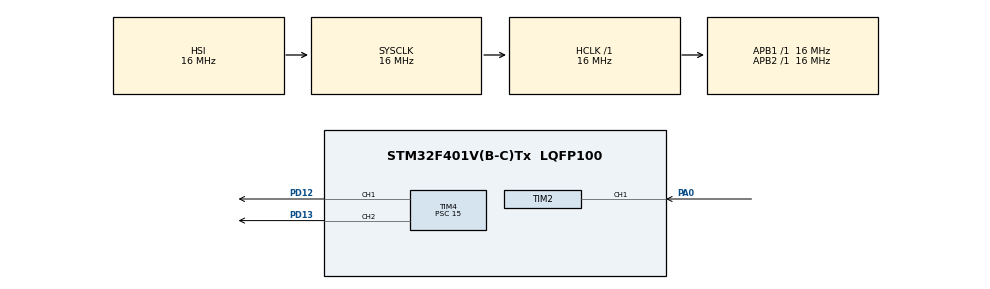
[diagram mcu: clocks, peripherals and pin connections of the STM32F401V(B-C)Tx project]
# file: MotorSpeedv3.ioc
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Mcu.Family=STM32F4
Mcu.Name=STM32F401V(B-C)Tx
Mcu.Package=LQFP100
NVIC.PriorityGroup=NVIC_PRIORITYGROUP_4
NVIC.TIM2_IRQn=true\:0\:0\:false\:false\:true\:true
NVIC.TIM4_IRQn=true\:0\:0\:false\:false\:true\:true
PA0-WKUP.Signal=S_TIM2_CH1_ETR
PD12.Signal=S_TIM4_CH1
PD13.Signal=S_TIM4_CH2
ProjectManager.HeapSize=0x200
ProjectManager.StackSize=0x400
ProjectManager.TargetToolchain=MDK-ARM V5
RCC.AHBFreq_Value=16000000
RCC.APB1Freq_Value=16000000
RCC.APB2Freq_Value=16000000
RCC.CortexFreq_Value=16000000
RCC.HSE_VALUE=25000000
RCC.HSI_VALUE=16000000
RCC.LSE_VALUE=32768
RCC.SYSCLKFreq_VALUE=16000000
RCC.VCOOutputFreq_Value=192000000
SH.S_TIM2_CH1_ETR.0=TIM2_CH1,Input_Capture1_from_TI1
SH.S_TIM4_CH1.0=TIM4_CH1,PWM Generation1 CH1
SH.S_TIM4_CH2.0=TIM4_CH2,PWM Generation2 CH2
TIM2.Channel-Input_Capture1_from_TI1=TIM_CHANNEL_1
TIM2.ICFilter_CH1=15
TIM2.Period=4294967295
TIM2.Prescaler=1599
TIM4.Channel-PWM\ Generation1\ CH1=TIM_CHANNEL_1
TIM4.Channel-PWM\ Generation2\ CH2=TIM_CHANNEL_2
TIM4.Period=99
TIM4.Prescaler=15
VP_TIM2_VS_ClockSourceINT.Mode=Internal
VP_TIM4_VS_ClockSourceINT.Mode=Internal
board=MotorSpeedv3

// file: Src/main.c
/**
  ******************************************************************************
  * File Name          : main.c
  * Description        : Main program body
  ******************************************************************************
  ** This notice applies to any and all portions of this file
  * that are not between comment pairs USER CODE BEGIN and
  * USER CODE END. Other portions of this file, whether
  * inserted by the user or by software development tools
  * are owned by their respective copyright owners.
  *
  * COPYRIGHT(c) 2017 STMicroelectronics
  *
  * Redistribution and use in source and binary forms, with or without modification,
  * are permitted provided that the following conditions are met:
  *   1. Redistributions of source code must retain the above copyright notice,
  *      this list of conditions and the following disclaimer.
  *   2. Redistributions in binary form must reproduce the above copyright notice,
  *      this list of conditions and the following disclaimer in the documentation
  *      and/or other materials provided with the distribution.
  *   3. Neither the name of STMicroelectronics nor the names of its contributors
  *      may be used to endorse or promote products derived from this software
  *      without specific prior written permission.
  *
  * THIS SOFTWARE IS PROVIDED BY THE COPYRIGHT HOLDERS AND CONTRIBUTORS "AS IS"
  * AND ANY EXPRESS OR IMPLIED WARRANTIES, INCLUDING, BUT NOT LIMITED TO, THE
  * IMPLIED WARRANTIES OF MERCHANTABILITY AND FITNESS FOR A PARTICULAR PURPOSE ARE
  * DISCLAIMED. IN NO EVENT SHALL THE COPYRIGHT HOLDER OR CONTRIBUTORS BE LIABLE
  * FOR ANY DIRECT, INDIRECT, INCIDENTAL, SPECIAL, EXEMPLARY, OR CONSEQUENTIAL
  * DAMAGES (INCLUDING, BUT NOT LIMITED TO, PROCUREMENT OF SUBSTITUTE GOODS OR
  * SERVICES; LOSS OF USE, DATA, OR PROFITS; OR BUSINESS INTERRUPTION) HOWEVER
  * CAUSED AND ON ANY THEORY OF LIABILITY, WHETHER IN CONTRACT, STRICT LIABILITY,
  * OR TORT (INCLUDING NEGLIGENCE OR OTHERWISE) ARISING IN ANY WAY OUT OF THE USE
  * OF THIS SOFTWARE, EVEN IF ADVISED OF THE POSSIBILITY OF SUCH DAMAGE.
  *
  ******************************************************************************
  */
#include "main.h"
#include "stm32f4xx_hal.h"

/* USER CODE BEGIN Includes */
#define SIZE 10
//#define KP 0.5
//#define KI 0.1
//#define KD 0.01
#define KP 1
#define KI 0.1
#define KD 0.1
/* USER CODE END Includes */

TIM_HandleTypeDef htim2;
TIM_HandleTypeDef htim4;

/* USER CODE BEGIN PV */
/* Private variables ---------------------------------------------------------*/
	int i = 0, j = 0;
	int pwm = 99, max_pwm = 99;
	int open_loop_speed = 270;
	int reference = 0;
	int slots = 20;
	long count = 0;
	int ticks = 0;
	long cur_val = 0, prev_val = 0;
	double speed_rpm = 0, avg_speed = 0, sum_speed = 0;
	double prev_speeds [SIZE];
	double PID = 0, Kp = 0, Ki = 0, Kd = 0;
	double delT = 0;
	double error = 0, prev_err = 0;
	double int_err = 0, der_err = 0;
/* USER CODE END PV */

void SystemClock_Config(void);
static void MX_GPIO_Init(void);
static void MX_TIM4_Init(void);
static void MX_TIM2_Init(void);

void HAL_TIM_MspPostInit(TIM_HandleTypeDef *htim);

/* USER CODE BEGIN PFP */
/* Private function prototypes -----------------------------------------------*/

/* USER CODE END PFP */

/* USER CODE BEGIN 0 */
void HAL_TIM_IC_CaptureCallback(TIM_HandleTypeDef *htim)
{
	if(htim->Instance==TIM2)
	{
		reference = 120;

		if(j >= SIZE) j = 0;
		prev_speeds[j++]= speed_rpm;

		prev_val = cur_val;
		cur_val = HAL_TIM_ReadCapturedValue(&htim2, TIM_CHANNEL_1);
    ticks = cur_val - prev_val;
		speed_rpm = (60 * 10000) / (ticks * slots);

		avg_speed = (speed_rpm + prev_speeds[0] + prev_speeds[1] + prev_speeds[2] + prev_speeds[3] + prev_speeds[4] + prev_speeds[5] + prev_speeds[6] + prev_speeds[7] + prev_speeds[8] + prev_speeds[9]) / 11;
		if (i++ == 0) error = 120;
		else error = reference - speed_rpm;
		delT = (double) ticks / 10000;

		int_err += (error * delT);
		der_err = (error - prev_err) / delT;
		PID = Kp*error + Ki*int_err + Kd*der_err;

//		pwm += ((max_pwm * PID) / reference);
		pwm += ((max_pwm * PID) / open_loop_speed);
		if(pwm > max_pwm) pwm = max_pwm;
		if(pwm < 0) pwm = 0;

		__HAL_TIM_SetCompare(&htim4, TIM_CHANNEL_1, pwm);
		prev_err = error;
	}
}

void HAL_TIM_PWM_PulseFinishedCallback(TIM_HandleTypeDef *htim)
{
	if(htim->Instance==TIM4)
	{
		count = __HAL_TIM_GetCounter(&htim2);
		if(count - cur_val >= 1000)
		{
			speed_rpm = 0;
			avg_speed = 0;
		}
	}
}
/* USER CODE END 0 */

int main(void)
{

  /* MCU Configuration----------------------------------------------------------*/

  /* Reset of all peripherals, Initializes the Flash interface and the Systick. */
  HAL_Init();

  /* Configure the system clock */
  SystemClock_Config();

  /* Initialize all configured peripherals */
  MX_GPIO_Init();
  MX_TIM4_Init();
  MX_TIM2_Init();

  /* USER CODE BEGIN 2 */
	HAL_TIM_PWM_Start_IT(&htim4, TIM_CHANNEL_1);
	HAL_TIM_PWM_Start(&htim4, TIM_CHANNEL_2);
	HAL_TIM_IC_Start_IT(&htim2, TIM_CHANNEL_1);

	Kp = KP;
	Ki = KI;
	Kd = KD;

	__HAL_TIM_SetCompare(&htim4, TIM_CHANNEL_1, pwm);
	__HAL_TIM_SetCompare(&htim4, TIM_CHANNEL_2, 0);
  /* USER CODE END 2 */

  /* Infinite loop */
  while (1)
  {

  }

}

/** System Clock Configuration
*/
void SystemClock_Config(void)
{

  RCC_OscInitTypeDef RCC_OscInitStruct;
  RCC_ClkInitTypeDef RCC_ClkInitStruct;

    /**Configure the main internal regulator output voltage
    */
  __HAL_RCC_PWR_CLK_ENABLE();

  __HAL_PWR_VOLTAGESCALING_CONFIG(PWR_REGULATOR_VOLTAGE_SCALE2);

    /**Initializes the CPU, AHB and APB busses clocks
    */
  RCC_OscInitStruct.OscillatorType = RCC_OSCILLATORTYPE_HSI;
  RCC_OscInitStruct.HSIState = RCC_HSI_ON;
  RCC_OscInitStruct.HSICalibrationValue = 16;
  RCC_OscInitStruct.PLL.PLLState = RCC_PLL_NONE;
  if (HAL_RCC_OscConfig(&RCC_OscInitStruct) != HAL_OK)
  {
    _Error_Handler(__FILE__, __LINE__);
  }

    /**Initializes the CPU, AHB and APB busses clocks
    */
  RCC_ClkInitStruct.ClockType = RCC_CLOCKTYPE_HCLK|RCC_CLOCKTYPE_SYSCLK
                              |RCC_CLOCKTYPE_PCLK1|RCC_CLOCKTYPE_PCLK2;
  RCC_ClkInitStruct.SYSCLKSource = RCC_SYSCLKSOURCE_HSI;
  RCC_ClkInitStruct.AHBCLKDivider = RCC_SYSCLK_DIV1;
  RCC_ClkInitStruct.APB1CLKDivider = RCC_HCLK_DIV1;
  RCC_ClkInitStruct.APB2CLKDivider = RCC_HCLK_DIV1;

  if (HAL_RCC_ClockConfig(&RCC_ClkInitStruct, FLASH_LATENCY_0) != HAL_OK)
  {
    _Error_Handler(__FILE__, __LINE__);
  }

    /**Configure the Systick interrupt time
    */
  HAL_SYSTICK_Config(HAL_RCC_GetHCLKFreq()/1000);

    /**Configure the Systick
    */
  HAL_SYSTICK_CLKSourceConfig(SYSTICK_CLKSOURCE_HCLK);

  /* SysTick_IRQn interrupt configuration */
  HAL_NVIC_SetPriority(SysTick_IRQn, 0, 0);
}

/* TIM2 init function */
static void MX_TIM2_Init(void)
{

  TIM_ClockConfigTypeDef sClockSourceConfig;
  TIM_MasterConfigTypeDef sMasterConfig;
  TIM_IC_InitTypeDef sConfigIC;

  htim2.Instance = TIM2;
  htim2.Init.Prescaler = 1599;
  htim2.Init.CounterMode = TIM_COUNTERMODE_UP;
  htim2.Init.Period = 4294967295;
  htim2.Init.ClockDivision = TIM_CLOCKDIVISION_DIV1;
  if (HAL_TIM_Base_Init(&htim2) != HAL_OK)
  {
    _Error_Handler(__FILE__, __LINE__);
  }

  sClockSourceConfig.ClockSource = TIM_CLOCKSOURCE_INTERNAL;
  if (HAL_TIM_ConfigClockSource(&htim2, &sClockSourceConfig) != HAL_OK)
  {
    _Error_Handler(__FILE__, __LINE__);
  }

  if (HAL_TIM_IC_Init(&htim2) != HAL_OK)
  {
    _Error_Handler(__FILE__, __LINE__);
  }

  sMasterConfig.MasterOutputTrigger = TIM_TRGO_RESET;
  sMasterConfig.MasterSlaveMode = TIM_MASTERSLAVEMODE_DISABLE;
  if (HAL_TIMEx_MasterConfigSynchronization(&htim2, &sMasterConfig) != HAL_OK)
  {
    _Error_Handler(__FILE__, __LINE__);
  }

  sConfigIC.ICPolarity = TIM_INPUTCHANNELPOLARITY_RISING;
  sConfigIC.ICSelection = TIM_ICSELECTION_DIRECTTI;
  sConfigIC.ICPrescaler = TIM_ICPSC_DIV1;
  sConfigIC.ICFilter = 15;
  if (HAL_TIM_IC_ConfigChannel(&htim2, &sConfigIC, TIM_CHANNEL_1) != HAL_OK)
  {
    _Error_Handler(__FILE__, __LINE__);
  }

}

/* TIM4 init function */
static void MX_TIM4_Init(void)
{

  TIM_ClockConfigTypeDef sClockSourceConfig;
  TIM_MasterConfigTypeDef sMasterConfig;
  TIM_OC_InitTypeDef sConfigOC;

  htim4.Instance = TIM4;
  htim4.Init.Prescaler = 15;
  htim4.Init.CounterMode = TIM_COUNTERMODE_UP;
  htim4.Init.Period = 99;
  htim4.Init.ClockDivision = TIM_CLOCKDIVISION_DIV1;
  if (HAL_TIM_Base_Init(&htim4) != HAL_OK)
  {
    _Error_Handler(__FILE__, __LINE__);
  }

  sClockSourceConfig.ClockSource = TIM_CLOCKSOURCE_INTERNAL;
  if (HAL_TIM_ConfigClockSource(&htim4, &sClockSourceConfig) != HAL_OK)
  {
    _Error_Handler(__FILE__, __LINE__);
  }

  if (HAL_TIM_PWM_Init(&htim4) != HAL_OK)
  {
    _Error_Handler(__FILE__, __LINE__);
  }

  sMasterConfig.MasterOutputTrigger = TIM_TRGO_RESET;
  sMasterConfig.MasterSlaveMode = TIM_MASTERSLAVEMODE_DISABLE;
  if (HAL_TIMEx_MasterConfigSynchronization(&htim4, &sMasterConfig) != HAL_OK)
  {
    _Error_Handler(__FILE__, __LINE__);
  }

  sConfigOC.OCMode = TIM_OCMODE_PWM1;
  sConfigOC.Pulse = 0;
  sConfigOC.OCPolarity = TIM_OCPOLARITY_HIGH;
  sConfigOC.OCFastMode = TIM_OCFAST_DISABLE;
  if (HAL_TIM_PWM_ConfigChannel(&htim4, &sConfigOC, TIM_CHANNEL_1) != HAL_OK)
  {
    _Error_Handler(__FILE__, __LINE__);
  }

  if (HAL_TIM_PWM_ConfigChannel(&htim4, &sConfigOC, TIM_CHANNEL_2) != HAL_OK)
  {
    _Error_Handler(__FILE__, __LINE__);
  }

  HAL_TIM_MspPostInit(&htim4);

}

/** Pinout Configuration
*/
static void MX_GPIO_Init(void)
{

  /* GPIO Ports Clock Enable */
  __HAL_RCC_GPIOA_CLK_ENABLE();
  __HAL_RCC_GPIOD_CLK_ENABLE();

}

void _Error_Handler(char * file, int line)
{
  while(1)
  {
  }
}

/************************ (C) COPYRIGHT STMicroelectronics *****END OF FILE****/
